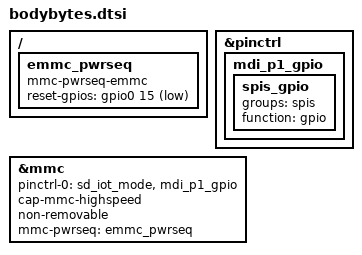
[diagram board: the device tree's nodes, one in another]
/* Bodybytes board overrides — appended to mediatek,mt7628-rfb.dts at build time
 * via CONFIG_DEVICE_TREE_INCLUDES in bodybytes.config.
 */

#include <dt-bindings/gpio/gpio.h>

&pinctrl {
	/*
	 * Set SPIS_MODE = gpio so the MDI P1 pads become GPIO#14-17.
	 * Required for the eMMC reset (MDI_TN_P1 = GPIO#15) and the
	 * recovery-boot sensor input (MDI_TP_P1 = GPIO#14).
	 */
	mdi_p1_gpio: mdi_p1_gpio {
		spis_gpio {
			groups = "spis";
			function = "gpio";
		};
	};
};

/ {
	/*
	 * eMMC hardware reset: MDI_TN_P1 (SoC pin 42, GPIO#15, gpio0 offset 15).
	 * Pulsed low on power-up to clear fault conditions.
	 */
	emmc_pwrseq: emmc_pwrseq {
		compatible = "mmc-pwrseq-emmc";
		reset-gpios = <&gpio0 15 GPIO_ACTIVE_LOW>;
	};
};

&mmc {
	/*
	 * sd_iot_mode: EPHY_APGIO_AIO_EN[4:1]=0xf (MDI pads → digital) +
	 * SD_MODE=0 (SDXC signals on EPHY P3/P4 pads) + ESD=0 (IoT routing).
	 * The base RFB defconfig uses sd_router_mode which remaps i2c/uart1/sdmode
	 * as GPIO and would break those peripherals on this board.
	 *
	 * mdi_p1_gpio: SPIS_MODE=gpio so MDI_TN_P1 (GPIO#15) is usable as the
	 * eMMC reset output.
	 */
	pinctrl-0 = <&sd_iot_mode &mdi_p1_gpio>;

	/* eMMC is soldered — not a removable SD card */
	/delete-property/ cap-sd-highspeed;
	cap-mmc-highspeed;
	non-removable;

	mmc-pwrseq = <&emmc_pwrseq>;
};
